# PIC16F1619 register map
File version: 1.0
PIC16F1619 special function registers
Registers are 8-bit, read-write, reset 0x0 unless marked. A register's access mark holds for its fields unless they carry their own. Offsets are from the block's base; lines under a group give offsets from that group; [hi:lo] are bit positions; {n}, {i} and the like mark numbered series; 'fields as' and 'values as' point back to an identical list; <NAME> marks a mode.

## Memory map
0x00800000 CPU size 0xFF0 — Core registers
0x0080000C PORTA size 0x388
0x0080000D PORTB size 0x38A
0x0080000E PORTC size 0x38C
0x00800010 INTERRUPTS size 0x85 — Interrupt flags and enables
0x00800015 TIMER0 size 0x1
0x00800016 TIMER1 size 0x4
0x0080001A OTHER size 0xF1E — Other registers
0x0080001C TIMER2 size 0x4
0x00800095 SYSTEM size 0x67E — Reset, watchdog and pin options
0x00800098 OSCILLATOR size 0x3
0x0080009B ADC size 0x5 — Analog-to-digital converter
0x00800111 COMPARATORS size 0x5
0x00800117 REFERENCES size 0x3 — Voltage reference, DAC and SR latch
0x00800191 NVM size 0x6 — Flash and EEPROM access
0x00800199 EUSART size 0x7
0x00800211 MSSP size 0xC12 — Synchronous serial port
0x00800291 CCP size 0xB85 — Capture, compare and PWM
0x00800415 TIMER4 size 0x4
0x0080041C TIMER6 size 0x4
0x00800493 TIMER3 size 0x4
0x0080049A TIMER5 size 0x4
0x00800E0F PPS size 0x99 — Peripheral pin select

## CPU — Core registers
Base 0x00800000
0x00 INDF0 reset not defined — INDF0, data address 0x000
0x01 INDF1 reset not defined — INDF1, data address 0x001
0x02 PCL — PCL, data address 0x002
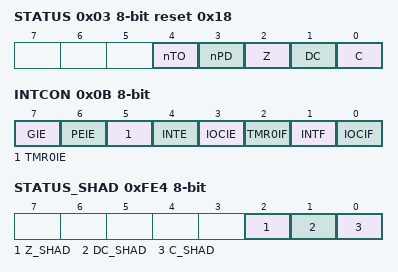
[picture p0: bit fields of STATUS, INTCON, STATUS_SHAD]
0x03 STATUS reset 0x18 — STATUS, data address 0x003
  [4] nTO, [3] nPD, [2] Z, [1] DC, [0] C
0x04 FSR0L — FSR0L, data address 0x004
0x05 FSR0H — FSR0H, data address 0x005
0x06 FSR1L — FSR1L, data address 0x006
0x07 FSR1H — FSR1H, data address 0x007
0x08 BSR — BSR, data address 0x008
  [4:0] BSR
0x09 WREG — WREG, data address 0x009
  [7:0] WREG0
0x0A PCLATH — PCLATH, data address 0x00a
  [6:0] PCLATH
0x0B INTCON — INTCON, data address 0x00b
  [7] GIE, [6] PEIE, [5] TMR0IE, [4] INTE, [3] IOCIE, [2] TMR0IF, [1] INTF, [0] IOCIF
0xFE4 STATUS_SHAD reset not defined — STATUS_SHAD, data address 0xfe4
  [2] Z_SHAD, [1] DC_SHAD, [0] C_SHAD
0xFE5 WREG_SHAD reset not defined — WREG_SHAD, data address 0xfe5
0xFE6 BSR_SHAD reset not defined — BSR_SHAD, data address 0xfe6
  [4:0] BSR_SHAD
0xFE7 PCLATH_SHAD reset not defined — PCLATH_SHAD, data address 0xfe7
  [6:0] PCLATH_SHAD
0xFE8 FSR0L_SHAD reset not defined — FSR0L_SHAD, data address 0xfe8
0xFE9 FSR0H_SHAD reset not defined — FSR0H_SHAD, data address 0xfe9
0xFEA FSR1L_SHAD reset not defined — FSR1L_SHAD, data address 0xfea
0xFEB FSR1H_SHAD reset not defined — FSR1H_SHAD, data address 0xfeb
0xFED STKPTR reset 0x1F — STKPTR, data address 0xfed
  [4:0] STKPTR
0xFEE TOSL reset not defined — TOSL, data address 0xfee
0xFEF TOSH reset not defined — TOSH, data address 0xfef
  [6:0] TOSH

## ADC — Analog-to-digital converter
Base 0x0080009B
0x00 ADRESL reset not defined — ADRESL, data address 0x09b
0x01 ADRESH reset not defined — ADRESH, data address 0x09c
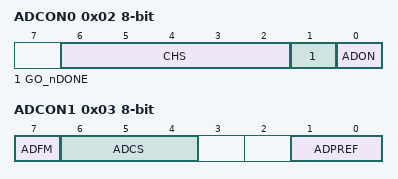
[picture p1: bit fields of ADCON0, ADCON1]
0x02 ADCON0 — ADCON0, data address 0x09d
  [6:2] CHS, [1] GO_nDONE, [0] ADON
0x03 ADCON1 — ADCON1, data address 0x09e
  [7] ADFM, [6:4] ADCS, [1:0] ADPREF
0x04 ADCON2 — ADCON2, data address 0x09f
  [7:3] TRIGSEL

## CCP — Capture, compare and PWM
Base 0x00800291
0x00 CCPR1L reset not defined — CCPR1L, data address 0x291
  [7:0] RL
0x01 CCPR1H reset not defined — CCPR1H, data address 0x292
  [7:0] RH
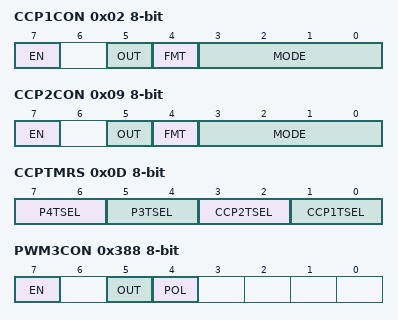
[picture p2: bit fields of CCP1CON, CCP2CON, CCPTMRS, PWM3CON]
0x02 CCP1CON — CCP1CON, data address 0x293
  [7] EN, [5] OUT, [4] FMT, [3:0] MODE
0x03 CCP1CAP (reset mask 0x7) — CCP1CAP, data address 0x294
  [7:0] CTS
0x07 CCPR2L reset not defined — CCPR2L, data address 0x298
  [7:0] RL
0x08 CCPR2H reset not defined — CCPR2H, data address 0x299
  [7:0] RH
0x09 CCP2CON — CCP2CON, data address 0x29a
  [7] EN, [5] OUT, [4] FMT, [3:0] MODE
0x0A CCP2CAP (reset mask 0x7) — CCP2CAP, data address 0x29b
  [7:0] CTS
0x0D CCPTMRS — CCPTMRS, data address 0x29e
  [7:6] P4TSEL, [5:4] P3TSEL, [3:2] CCP2TSEL, [1:0] CCP1TSEL
0x386 PWM3DCL reset not defined — PWM3DCL, data address 0x617
  [7:6] DC
0x387 PWM3DCH reset not defined — PWM3DCH, data address 0x618
  [7:0] DC
0x388 PWM3CON — PWM3CON, data address 0x619
  [7] EN, [5] OUT, [4] POL
0x389 PWM4DCL reset not defined — PWM4DCL, data address 0x61a
  [7:6] DC
0x38A PWM4DCH reset not defined — PWM4DCH, data address 0x61b
  [7:0] DC
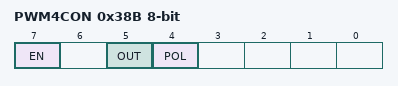
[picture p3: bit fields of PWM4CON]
0x38B PWM4CON — PWM4CON, data address 0x61c
  [7] EN, [5] OUT, [4] POL
0xB83 CCP1PPS reset 0x15 — CCP1PPS, data address 0xe14
  [4:0] CCP1PPS
0xB84 CCP2PPS reset 0x13 — CCP2PPS, data address 0xe15
  [4:0] CCP2PPS
